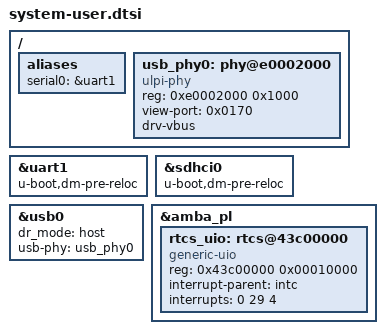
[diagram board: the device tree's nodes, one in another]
/include/ "system-conf.dtsi"

/ {
  aliases {
    serial0 = &uart1;
  };

  usb_phy0: phy@e0002000 {
    compatible = "ulpi-phy";
    #phy-cells = <0>;
    reg = <0xe0002000 0x1000>;
    view-port = <0x0170>;
    drv-vbus;
  };
};

&uart1 {
  u-boot,dm-pre-reloc;
  status = "okay";
};

&sdhci0 {
  u-boot,dm-pre-reloc;
  status = "okay";
};

&usb0 {
  status = "okay";
  dr_mode = "host";
  usb-phy = <&usb_phy0>;
};

&amba_pl {
  rtcs_uio: rtcs@43c00000 {
    compatible = "generic-uio";
    reg = <0x43c00000 0x00010000>;
    interrupt-parent = <&intc>;
    interrupts = <0 29 4>;
    status = "okay";
  };
};
